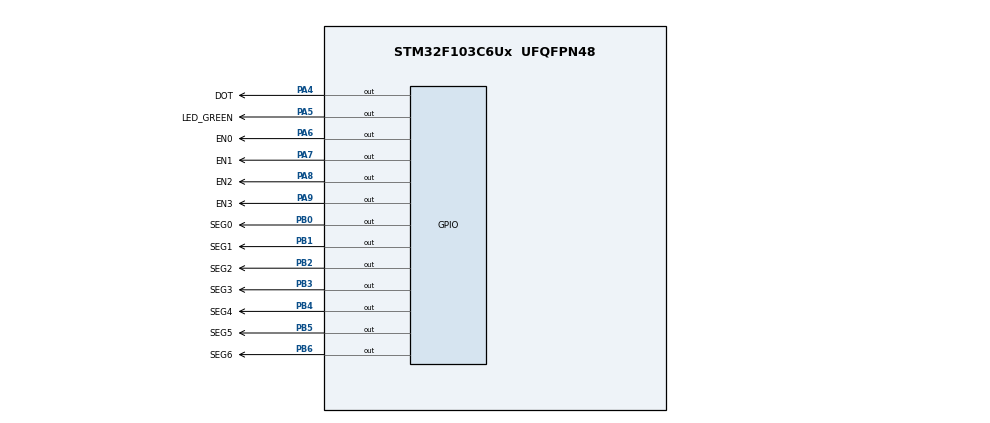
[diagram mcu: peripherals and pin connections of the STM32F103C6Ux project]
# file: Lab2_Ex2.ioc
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Mcu.Family=STM32F1
Mcu.Name=STM32F103C6Ux
Mcu.Package=UFQFPN48
NVIC.PriorityGroup=NVIC_PRIORITYGROUP_4
NVIC.TIM2_IRQn=true\:0\:0\:false\:false\:true\:true\:true\:true
PA4.GPIO_Label=DOT
PA4.Signal=GPIO_Output
PA5.GPIO_Label=LED_GREEN
PA5.Signal=GPIO_Output
PA6.GPIO_Label=EN0
PA6.Signal=GPIO_Output
PA7.GPIO_Label=EN1
PA7.Signal=GPIO_Output
PA8.GPIO_Label=EN2
PA8.Signal=GPIO_Output
PA9.GPIO_Label=EN3
PA9.Signal=GPIO_Output
PB0.GPIO_Label=SEG0
PB0.Signal=GPIO_Output
PB1.GPIO_Label=SEG1
PB1.Signal=GPIO_Output
PB2.GPIO_Label=SEG2
PB2.Signal=GPIO_Output
PB3.GPIO_Label=SEG3
PB3.Signal=GPIO_Output
PB4.GPIO_Label=SEG4
PB4.Signal=GPIO_Output
PB5.GPIO_Label=SEG5
PB5.Signal=GPIO_Output
PB6.GPIO_Label=SEG6
PB6.Signal=GPIO_Output
ProjectManager.HeapSize=0x200
ProjectManager.StackSize=0x400
ProjectManager.TargetToolchain=STM32CubeIDE
RCC.APB1Freq_Value=8000000
RCC.APB2Freq_Value=8000000
TIM2.Period=9
TIM2.Prescaler=7999
VP_SYS_VS_ND.Mode=No_Debug
VP_TIM2_VS_ClockSourceINT.Mode=Internal
board=custom

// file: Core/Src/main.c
/* USER CODE BEGIN Header */
/**
  ******************************************************************************
  * @file           : main.c
  * @brief          : Main program body
  ******************************************************************************
  * @attention
  *
  * Copyright (c) 2026 STMicroelectronics.
  * All rights reserved.
  *
  * This software is licensed under terms that can be found in the LICENSE file
  * in the root directory of this software component.
  * If no LICENSE file comes with this software, it is provided AS-IS.
  *
  ******************************************************************************
  */
/* USER CODE END Header */
#include "main.h"

/* USER CODE BEGIN PTD */
typedef struct {
    GPIO_TypeDef* port;
    uint16_t pin;
} PinRef;
/* USER CODE END PTD */

TIM_HandleTypeDef htim2;

/* USER CODE BEGIN PV */
PinRef segPins[7] = {
    {SEG0_GPIO_Port, SEG0_Pin},   // a
    {SEG1_GPIO_Port, SEG1_Pin},   // b
    {SEG2_GPIO_Port, SEG2_Pin},   // c
    {SEG3_GPIO_Port, SEG3_Pin},   // d
    {SEG4_GPIO_Port, SEG4_Pin},   // e
    {SEG5_GPIO_Port, SEG5_Pin},   // f
    {SEG6_GPIO_Port, SEG6_Pin}    // g
};

// bit0=a, bit1=b, bit2=c, bit3=d, bit4=e, bit5=f, bit6=g — 1 = tắt (active-low, common-anode)
const uint8_t seg_table[10] = {
    0x40, // 0
    0x79, // 1
    0x24, // 2
    0x30, // 3
    0x19, // 4
    0x12, // 5
    0x02, // 6
    0x78, // 7
    0x00, // 8
    0x10  // 9
};
/* USER CODE END PV */

void SystemClock_Config(void);
static void MX_GPIO_Init(void);
static void MX_TIM2_Init(void);
/* USER CODE BEGIN PFP */
void display7SEG(int num);
/* USER CODE END PFP */

int main(void)
{

  /* MCU Configuration--------------------------------------------------------*/

  /* Reset of all peripherals, Initializes the Flash interface and the Systick. */
  HAL_Init();

  /* Configure the system clock */
  SystemClock_Config();

  /* Initialize all configured peripherals */
  MX_GPIO_Init();
  MX_TIM2_Init();
  /* USER CODE BEGIN 2 */
  HAL_TIM_Base_Start_IT(&htim2);
  /* USER CODE END 2 */

  /* Infinite loop */
  while (1)
  {

  }
}

void SystemClock_Config(void)
{
  RCC_OscInitTypeDef RCC_OscInitStruct = {0};
  RCC_ClkInitTypeDef RCC_ClkInitStruct = {0};

  /** Initializes the RCC Oscillators according to the specified parameters
  * in the RCC_OscInitTypeDef structure.
  */
  RCC_OscInitStruct.OscillatorType = RCC_OSCILLATORTYPE_HSI;
  RCC_OscInitStruct.HSIState = RCC_HSI_ON;
  RCC_OscInitStruct.HSICalibrationValue = RCC_HSICALIBRATION_DEFAULT;
  RCC_OscInitStruct.PLL.PLLState = RCC_PLL_NONE;
  if (HAL_RCC_OscConfig(&RCC_OscInitStruct) != HAL_OK)
  {
    Error_Handler();
  }

  /** Initializes the CPU, AHB and APB buses clocks
  */
  RCC_ClkInitStruct.ClockType = RCC_CLOCKTYPE_HCLK|RCC_CLOCKTYPE_SYSCLK
                              |RCC_CLOCKTYPE_PCLK1|RCC_CLOCKTYPE_PCLK2;
  RCC_ClkInitStruct.SYSCLKSource = RCC_SYSCLKSOURCE_HSI;
  RCC_ClkInitStruct.AHBCLKDivider = RCC_SYSCLK_DIV1;
  RCC_ClkInitStruct.APB1CLKDivider = RCC_HCLK_DIV1;
  RCC_ClkInitStruct.APB2CLKDivider = RCC_HCLK_DIV1;

  if (HAL_RCC_ClockConfig(&RCC_ClkInitStruct, FLASH_LATENCY_0) != HAL_OK)
  {
    Error_Handler();
  }
}

static void MX_TIM2_Init(void)
{

  TIM_ClockConfigTypeDef sClockSourceConfig = {0};
  TIM_MasterConfigTypeDef sMasterConfig = {0};

  htim2.Instance = TIM2;
  htim2.Init.Prescaler = 7999;
  htim2.Init.CounterMode = TIM_COUNTERMODE_UP;
  htim2.Init.Period = 9;
  htim2.Init.ClockDivision = TIM_CLOCKDIVISION_DIV1;
  htim2.Init.AutoReloadPreload = TIM_AUTORELOAD_PRELOAD_DISABLE;
  if (HAL_TIM_Base_Init(&htim2) != HAL_OK)
  {
    Error_Handler();
  }
  sClockSourceConfig.ClockSource = TIM_CLOCKSOURCE_INTERNAL;
  if (HAL_TIM_ConfigClockSource(&htim2, &sClockSourceConfig) != HAL_OK)
  {
    Error_Handler();
  }
  sMasterConfig.MasterOutputTrigger = TIM_TRGO_RESET;
  sMasterConfig.MasterSlaveMode = TIM_MASTERSLAVEMODE_DISABLE;
  if (HAL_TIMEx_MasterConfigSynchronization(&htim2, &sMasterConfig) != HAL_OK)
  {
    Error_Handler();
  }

}

static void MX_GPIO_Init(void)
{
  GPIO_InitTypeDef GPIO_InitStruct = {0};

  /* GPIO Ports Clock Enable */
  __HAL_RCC_GPIOA_CLK_ENABLE();
  __HAL_RCC_GPIOB_CLK_ENABLE();

  /*Configure GPIO pin Output Level */
  HAL_GPIO_WritePin(GPIOA, DOT_Pin|LED_RED_Pin|EN0_Pin|EN1_Pin
                          |EN2_Pin|EN3_Pin, GPIO_PIN_RESET);

  /*Configure GPIO pin Output Level */
  HAL_GPIO_WritePin(GPIOB, SEG0_Pin|SEG1_Pin|SEG2_Pin|SEG3_Pin
                          |SEG4_Pin|SEG5_Pin|SEG6_Pin, GPIO_PIN_RESET);

  /*Configure GPIO pins : DOT_Pin LED_RED_Pin EN0_Pin EN1_Pin
                           EN2_Pin EN3_Pin */
  GPIO_InitStruct.Pin = DOT_Pin|LED_RED_Pin|EN0_Pin|EN1_Pin
                          |EN2_Pin|EN3_Pin;
  GPIO_InitStruct.Mode = GPIO_MODE_OUTPUT_PP;
  GPIO_InitStruct.Pull = GPIO_NOPULL;
  GPIO_InitStruct.Speed = GPIO_SPEED_FREQ_LOW;
  HAL_GPIO_Init(GPIOA, &GPIO_InitStruct);

  /*Configure GPIO pins : SEG0_Pin SEG1_Pin SEG2_Pin SEG3_Pin
                           SEG4_Pin SEG5_Pin SEG6_Pin */
  GPIO_InitStruct.Pin = SEG0_Pin|SEG1_Pin|SEG2_Pin|SEG3_Pin
                          |SEG4_Pin|SEG5_Pin|SEG6_Pin;
  GPIO_InitStruct.Mode = GPIO_MODE_OUTPUT_PP;
  GPIO_InitStruct.Pull = GPIO_NOPULL;
  GPIO_InitStruct.Speed = GPIO_SPEED_FREQ_LOW;
  HAL_GPIO_Init(GPIOB, &GPIO_InitStruct);

}

/* USER CODE BEGIN 4 */
void display7SEG(int num) {
    if (num < 0 || num > 9) return;   // validate input, tránh truy cập ngoài mảng

    uint8_t pattern = seg_table[num];

    for (int i = 0; i < 7; i++) {
        GPIO_PinState state = ((pattern >> i) & 0x01) ? GPIO_PIN_SET : GPIO_PIN_RESET;
        HAL_GPIO_WritePin(segPins[i].port, segPins[i].pin, state);
    }
}
int digitToShow[4] = {1, 2 , 3, 0};
int activeDigit = 0;
int digitTick = 0, dotTick = 0;
const int DIGIT_INTERVAL = 50;
const int DOT_INTERVAL = 100;
PinRef enPins[4] = {{EN0_GPIO_Port, EN0_Pin}, {EN1_GPIO_Port, EN1_Pin},
					{EN2_GPIO_Port, EN2_Pin}, {EN3_GPIO_Port, EN3_Pin}};

void HAL_TIM_PeriodElapsedCallback(TIM_HandleTypeDef *htim){
	digitTick++;
	if (digitTick >= DIGIT_INTERVAL){
		digitTick = 0;
		for (int i = 0; i<4; i++){
			HAL_GPIO_WritePin(enPins[i].port,enPins[i].pin, GPIO_PIN_SET);
		}
		activeDigit = (activeDigit + 1) % 4;
		display7SEG(digitToShow[activeDigit]);
		HAL_GPIO_WritePin(enPins[activeDigit].port, enPins[activeDigit].pin, GPIO_PIN_RESET);
	}
	dotTick++;
	if (dotTick >= DOT_INTERVAL){
		dotTick = 0;
		HAL_GPIO_TogglePin(DOT_GPIO_Port, DOT_Pin);
	}
}
/* USER CODE END 4 */

void Error_Handler(void)
{
  __disable_irq();
  while (1)
  {
  }
}
